# STM32MP21_CA35 register map
File version: 0.4
CPU: CM33 r0p1, little endian, MPU, FPU, vendor SysTick, 8 interrupt priority bits
Registers are 32-bit, read-write, reset 0x0 unless marked. A register's access mark holds for its fields unless they carry their own. Offsets are from the block's base; [hi:lo] are bit positions; {n}, {i} and the like mark numbered series; 'fields as' and 'values as' point back to an identical list.

## RTC — RTC register block
Base 0x46000000
Same registers: RTC_S 0x56000000
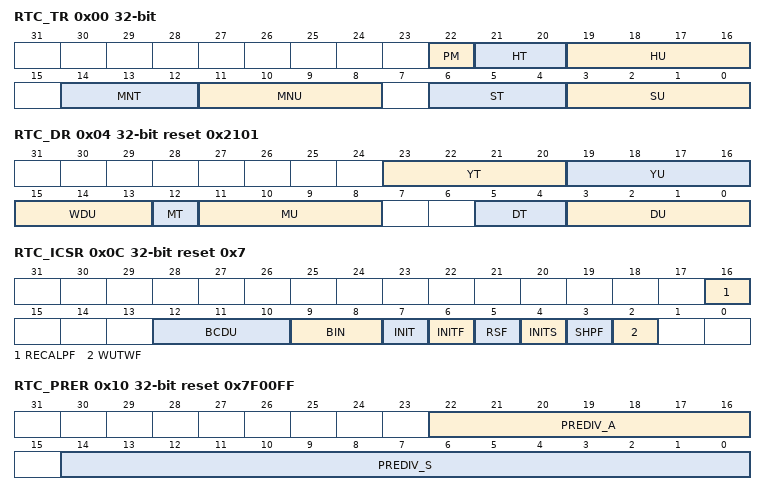
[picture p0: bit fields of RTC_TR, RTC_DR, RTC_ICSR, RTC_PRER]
0x00 RTC_TR — RTC time register
  [22] PM — AM/PM notation
    0=AM or 24-hour format; 1=PM
  [21:20] HT — Hour tens in BCD format
  [19:16] HU — Hour units in BCD format
  [14:12] MNT — Minute tens in BCD format
  [11:8] MNU — Minute units in BCD format
  [6:4] ST — Second tens in BCD format
  [3:0] SU — Second units in BCD format
0x04 RTC_DR reset 0x2101 — RTC date register
  [23:20] YT — Year tens in BCD format
  [19:16] YU — Year units in BCD format
  [15:13] WDU — Week day units
    0=forbidden; 1=Monday; 7=Sunday
  [12] MT — Month tens in BCD format
  [11:8] MU — Month units in BCD format
  [5:4] DT — Date tens in BCD format
  [3:0] DU — Date units in BCD format
0x08 RTC_SSR ro — RTC subsecond register
  [31:0] SS — Synchronous binary counter
0x0C RTC_ICSR reset 0x7 — RTC initialization control and status register
  [16] RECALPF ro — Recalibration pending Flag
  [12:10] BCDU — BCD update (BIN = 10 or 11)
    {v}=1s calendar increment is generated each time SS[{v+7}:0] = 0 (v=0..7)
  [9:8] BIN — Binary mode
    0=Free running BCD calendar mode (Binary mode disabled); 1=Free running Binary mode (BCD mode disabled); 2=Free running BCD calendar and Binary modes; 3=Free running BCD calendar and Binary modes
  [7] INIT — Initialization mode
    0=Free running mode; 1=Initialization mode used to program time and date register (RTC_TR and RTC_DR), and prescaler register (RTC_PRER), plus BIN and BCDU fields
  [6] INITF ro — Initialization flag
    0=Calendar registers update is not allowed; 1=Calendar registers update is allowed
  [5] RSF — Registers synchronization flag
    0=Calendar shadow registers not yet synchronized; 1=Calendar shadow registers synchronized
  [4] INITS ro — Initialization status flag
    0=Calendar has not been initialized; 1=Calendar has been initialized
  [3] SHPF ro — Shift operation pending
    0=No shift operation is pending; 1=A shift operation is pending
  [2] WUTWF ro — Wake-up timer write flag
    0=Wake-up timer configuration update not allowed except in initialization mode; 1=Wake-up timer configuration update allowed
0x10 RTC_PRER reset 0x7F00FF — RTC prescaler register
  [22:16] PREDIV_A — Asynchronous prescaler factor
  [14:0] PREDIV_S — Synchronous prescaler factor
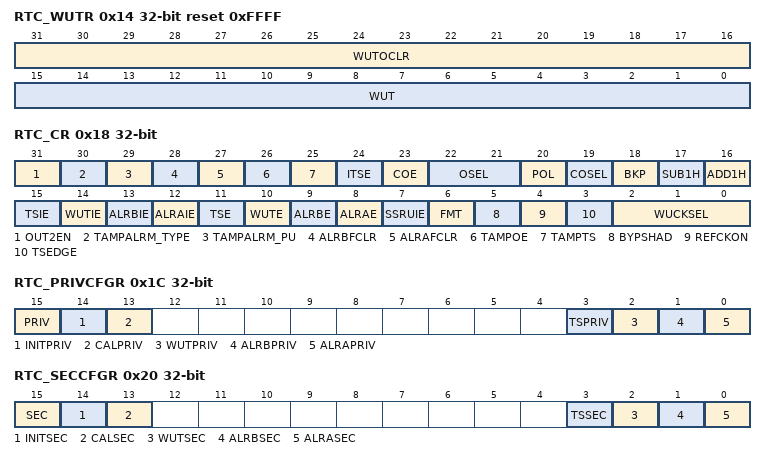
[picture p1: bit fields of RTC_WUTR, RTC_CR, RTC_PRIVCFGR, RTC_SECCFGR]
0x14 RTC_WUTR reset 0xFFFF — RTC wake-up timer register
  [31:16] WUTOCLR — Wake-up auto-reload output clear value
  [15:0] WUT — Wake-up auto-reload value bits
0x18 RTC_CR — RTC control register
  [31] OUT2EN — RTC_OUT2 output enable
  [30] TAMPALRM_TYPE — TAMPALRM output type
    0=TAMPALRM is push-pull output; 1=TAMPALRM is open-drain output
  [29] TAMPALRM_PU — TAMPALRM pull-up enable
    0=No pull-up is applied on TAMPALRM output; 1=A pull-up is applied on TAMPALRM output
  [28] ALRBFCLR — Alarm B flag automatic clear
    0=Alarm B event generates a trigger event and ALRBF must be cleared by software to allow next alarm event; 1=Alarm B event generates a trigger event
  [27] ALRAFCLR — Alarm A flag automatic clear
    0=Alarm A event generates a trigger event and ALRAF must be cleared by software to allow next alarm event; 1=Alarm A event generates a trigger event
  [26] TAMPOE — Tamper detection output enable on TAMPALRM
    0=The tamper flag is not routed on TAMPALRM; 1=The tamper flag is routed on TAMPALRM, combined with the signal provided by OSEL and with the polarity provided by POL
  [25] TAMPTS — Activate timestamp on tamper detection event
    0=Tamper detection event does not cause a RTC timestamp to be saved; 1=Save RTC timestamp on tamper detection event
  [24] ITSE — timestamp on internal event enable
    0=internal event timestamp disabled; 1=internal event timestamp enabled
  [23] COE — Calibration output enable
    0=Calibration output disabled; 1=Calibration output enabled
  [22:21] OSEL — Output selection
    0=Output disabled; 1=Alarm A output enabled; 2=Alarm B output enabled; 3=Wake-up output enabled
  [20] POL — Output polarity
    0=The pin is high when ALRAF/ALRBF/WUTF is asserted (depending on OSEL[1:0]), or when a TAMPxF/ITAMPxF is asserted (if TAMPOE = 1); 1=The pin is low when ALRAF/ALRBF/WUTF is asserted (depending on OSEL[1:0]), or when a TAMPxF/ITAMPxF is asserted (if TAMPOE = 1)
  [19] COSEL — Calibration output selection
    0=Calibration output is 512Hz; 1=Calibration output is 1Hz
  [18] BKP — Backup
  [17] SUB1H wo — Subtract 1 hour (winter time change)
    0=No effect; 1=Subtracts 1 hour to the current time
  [16] ADD1H wo — Add 1 hour (summer time change)
    0=No effect; 1=Adds 1 hour to the current time
  [15] TSIE — Timestamp interrupt enable
    0=Timestamp interrupt disable; 1=Timestamp interrupt enable
  [14] WUTIE — Wake-up timer interrupt enable
    0=Wake-up timer interrupt disabled; 1=Wake-up timer interrupt enabled
  [13] ALRBIE — Alarm B interrupt enable
    0=Alarm B interrupt disable; 1=Alarm B interrupt enable
  [12] ALRAIE — Alarm A interrupt enable
    0=Alarm A interrupt disabled; 1=Alarm A interrupt enabled
  [11] TSE — timestamp enable
    0=timestamp disable; 1=timestamp enable
  [10] WUTE — Wake-up timer enable
    0=Wake-up timer disabled; 1=Wake-up timer enabled
  [9] ALRBE — Alarm B enable
    0=Alarm B disabled; 1=Alarm B enabled
  [8] ALRAE — Alarm A enable
    0=Alarm A disabled; 1=Alarm A enabled
  [7] SSRUIE — SSR underflow interrupt enable
    0=SSR underflow interrupt disabled; 1=SSR underflow interrupt enabled
  [6] FMT — Hour format
    0=24 hour/day format; 1=AM/PM hour format
  [5] BYPSHAD — Bypass the shadow registers
    0=Calendar values (when reading from RTC_SSR, RTC_TR, and RTC_DR) are taken from the shadow registers, which are updated once every two RTCCLK cycles; 1=Calendar values (when reading from RTC_SSR, RTC_TR, and RTC_DR) are taken directly from the calendar counters
  [4] REFCKON — RTC_REFIN reference clock detection enable (50 or 60Hz)
    0=RTC_REFIN detection disabled; 1=RTC_REFIN detection enabled
  [3] TSEDGE — Timestamp event active edge
    0=RTC_TS input rising edge generates a timestamp event; 1=RTC_TS input falling edge generates a timestamp event
  [2:0] WUCKSEL — ck_wut wake-up clock selection
    0=RTC/16 clock is selected; 1=RTC/8 clock is selected; 2=RTC/4 clock is selected; 3=RTC/2 clock is selected
0x1C RTC_PRIVCFGR — RTC privilege mode control register
  [15] PRIV — RTC privilege protection
    0=All RTC registers can be written when the APB access is privileged or non-privileged, except the registers protected by other privilege protection bits; 1=All RTC registers can be written only when the APB access is privileged
  [14] INITPRIV — Initialization privilege protection
    0=RTC Initialization mode, calendar and prescalers registers can be written when the APB access is privileged or non-privileged; 1=RTC Initialization mode, calendar and prescalers registers can be written only when the APB access is privileged
  [13] CALPRIV — Shift register, Delight saving, calibration and reference clock privilege protection
    0=Shift register, Delight saving, calibration and reference clock can be written when the APB access is privileged or non-privileged; 1=Shift register, Delight saving, calibration and reference clock can be written only when the APB access is privileged
  [3] TSPRIV — Timestamp privilege protection
    0=RTC Timestamp configuration and interrupt clear can be written when the APB access is privileged or non-privileged; 1=RTC Timestamp configuration and interrupt clear can be written only when the APB access is privileged
  [2] WUTPRIV — Wake-up timer privilege protection
    0=RTC wake-up timer configuration and interrupt clear can be written when the APB access is privileged or non-privileged; 1=RTC wake-up timer configuration and interrupt clear can be written only when the APB access is privileged
  [1] ALRBPRIV — Alarm B privilege protection
    0=RTC Alarm B configuration and interrupt clear can be written when the APB access is privileged or non-privileged; 1=RTC Alarm B configuration and interrupt clear can be written only when the APB access is privileged
  [0] ALRAPRIV — Alarm A and SSR underflow privilege protection
    0=RTC Alarm A and SSR underflow configuration and interrupt clear can be written when the APB access is privileged or non-privileged; 1=RTC Alarm A and SSR underflow configuration and interrupt clear can be written only when the APB access is privileged
0x20 RTC_SECCFGR — RTC secure configuration register
  [15] SEC — RTC global protection
    0=All RTC registers can be written when the APB access is secure or non-secure, except the registers protected by other secure protection bits; 1=All RTC registers can be written only when the APB access is secure
  [14] INITSEC — Initialization protection
    0=RTC Initialization mode, calendar and prescalers registers can be written when the APB access is secure or nonsecure; 1=RTC Initialization mode, calendar and prescalers registers can be written only when the APB access is secure
  [13] CALSEC — Shift register, daylight saving, calibration and reference clock protection
    0=Shift register, daylight saving, calibration and reference clock can be written when the APB access is secure or nonsecure; 1=Shift register, daylight saving, calibration and reference clock can be written only when the APB access is secure
  [3] TSSEC — Timestamp protection
    0=RTC timestamp configuration and interrupt clear can be written when the APB access is secure or nonsecure; 1=RTC timestamp configuration and interrupt clear can be written only when the APB access is secure
  [2] WUTSEC — Wake-up timer protection
    0=RTC wake-up timer configuration and interrupt clear can be written when the APB access is secure or nonsecure; 1=RTC wake-up timer configuration and interrupt clear can be written only when the APB access is secure
  [1] ALRBSEC — Alarm B protection
    0=RTC alarm B configuration and interrupt clear can be written when the APB access is secure or nonsecure; 1=RTC alarm B configuration and interrupt clear can be written only when the APB access is secure
  [0] ALRASEC — Alarm A and SSR underflow protection
    0=RTC alarm A and SSR underflow configuration and interrupt clear can be written when the APB access is secure or nonsecure; 1=RTC alarm A and SSR underflow configuration and interrupt clear can be written only when the APB access is secure
0x24 RTC_WPR wo — RTC write protection register
  [7:0] KEY — Write protection key
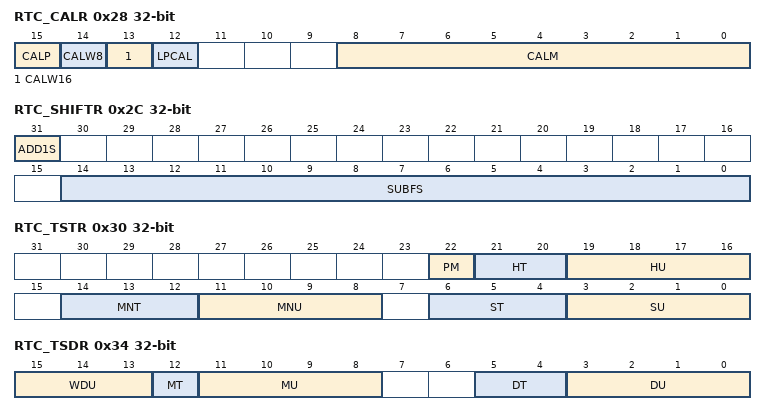
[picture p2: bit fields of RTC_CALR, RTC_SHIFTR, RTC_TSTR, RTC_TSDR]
0x28 RTC_CALR — RTC calibration register
  [15] CALP — Increase frequency of RTC by 488.
    0=No RTCCLK pulses are added; 1=One RTCCLK pulse is effectively inserted every 2less thansup>11less than/sup> pulses (frequency increased by 488
  [14] CALW8 — Use an 8-second calibration cycle period
  [13] CALW16 — Use a 16-second calibration cycle period
  [12] LPCAL — RTC low-power mode
    0=Calibration window is 2less thansup>20less than/sup> RTCCLK, which is a high-consumption mode; 1=Calibration window is 2less thansup>20less than/sup> ck_apre, which is the required configuration for ultra-low consumption mode
  [8:0] CALM — Calibration minus
0x2C RTC_SHIFTR wo — RTC shift control register
  [31] ADD1S — Add one second
    0=No effect; 1=Add one second to the clock/calendar
  [14:0] SUBFS — Subtract a fraction of a second
0x30 RTC_TSTR ro — RTC timestamp time register
  [22] PM — AM/PM notation
    0=AM or 24-hour format; 1=PM
  [21:20] HT — Hour tens in BCD format.
  [19:16] HU — Hour units in BCD format.
  [14:12] MNT — Minute tens in BCD format.
  [11:8] MNU — Minute units in BCD format.
  [6:4] ST — Second tens in BCD format.
  [3:0] SU — Second units in BCD format.
0x34 RTC_TSDR ro — RTC timestamp date register
  [15:13] WDU — Week day units
  [12] MT — Month tens in BCD format
  [11:8] MU — Month units in BCD format
  [5:4] DT — Date tens in BCD format
  [3:0] DU — Date units in BCD format
0x38 RTC_TSSSR ro — RTC timestamp subsecond register
  [31:0] SS — Subsecond value/synchronous binary counter values
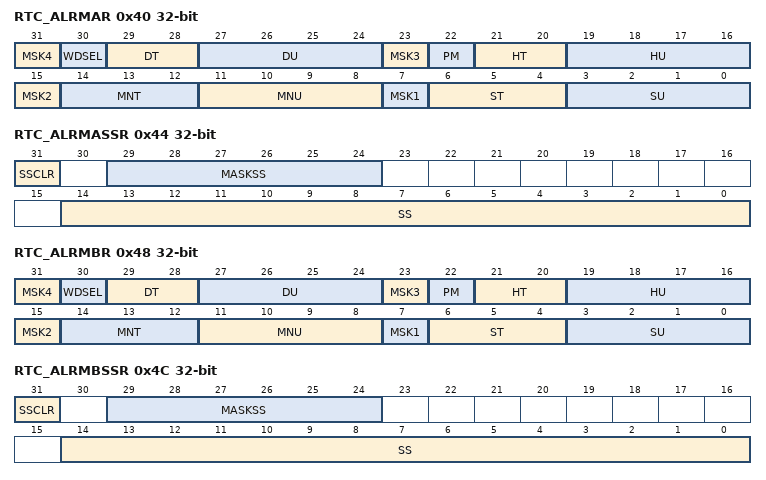
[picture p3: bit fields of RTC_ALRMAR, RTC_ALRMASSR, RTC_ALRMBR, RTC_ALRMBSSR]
0x40 RTC_ALRMAR — RTC alarm A register
  [31] MSK4 — Alarm A date mask
    0=Alarm A set if the date/day match; 1=Date/day don't care in alarm A comparison
  [30] WDSEL — Week day selection
    0=DU[3:0] represents the date units; 1=DU[3:0] represents the week day
  [29:28] DT — Date tens in BCD format
  [27:24] DU — Date units or day in BCD format
  [23] MSK3 — Alarm A hours mask
    0=Alarm A set if the hours match; 1=Hours don't care in alarm A comparison
  [22] PM — AM/PM notation
    0=AM or 24-hour format; 1=PM
  [21:20] HT — Hour tens in BCD format
  [19:16] HU — Hour units in BCD format
  [15] MSK2 — Alarm A minutes mask
    0=Alarm A set if the minutes match; 1=Minutes don't care in alarm A comparison
  [14:12] MNT — Minute tens in BCD format
  [11:8] MNU — Minute units in BCD format
  [7] MSK1 — Alarm A seconds mask
    0=Alarm A set if the seconds match; 1=Seconds don't care in alarm A comparison
  [6:4] ST — Second tens in BCD format.
  [3:0] SU — Second units in BCD format.
0x44 RTC_ALRMASSR — RTC alarm A subsecond register
  [31] SSCLR — Clear synchronous counter on alarm (Binary mode only)
    0=The synchronous binary counter (SS[31:0] in RTC_SSR) is free-running; 1=The synchronous binary counter (SS[31:0] in RTC_SSR) is running from 0xFFFFFFFF to RTC_ALRABINR
  [29:24] MASKSS — Mask the most-significant bits starting at this bit
    0=No comparison on subseconds for Alarm A; 1=SS[31:1] are don't care in Alarm A comparison
  [14:0] SS — Subseconds value
0x48 RTC_ALRMBR — RTC alarm B register
  [31] MSK4 — Alarm B date mask
    0=Alarm B set if the date and day match; 1=Date and day don't care in alarm B comparison
  [30] WDSEL — Week day selection
    values as RTC_ALRMAR.WDSEL
  [29:28] DT — Date tens in BCD format
  [27:24] DU — Date units or day in BCD format
  [23] MSK3 — Alarm B hours mask
    0=Alarm B set if the hours match; 1=Hours don't care in alarm B comparison
  [22] PM — AM/PM notation
    0=AM or 24-hour format; 1=PM
  [21:20] HT — Hour tens in BCD format
  [19:16] HU — Hour units in BCD format
  [15] MSK2 — Alarm B minutes mask
    0=Alarm B set if the minutes match; 1=Minutes don't care in alarm B comparison
  [14:12] MNT — Minute tens in BCD format
  [11:8] MNU — Minute units in BCD format
  [7] MSK1 — Alarm B seconds mask
    0=Alarm B set if the seconds match; 1=Seconds don't care in alarm B comparison
  [6:4] ST — Second tens in BCD format
  [3:0] SU — Second units in BCD format
0x4C RTC_ALRMBSSR — RTC alarm B subsecond register
  [31] SSCLR — Clear synchronous counter on alarm (Binary mode only)
    0=The synchronous binary counter (SS[31:0] in RTC_SSR) is free-running; 1=The synchronous binary counter (SS[31:0] in RTC_SSR) is running from 0xFFFFFFFF to RTC_ALRBBINR
  [29:24] MASKSS — Mask the most-significant bits starting at this bit
    0=No comparison on subseconds for Alarm B; 1=SS[31:1] are don't care in Alarm B comparison
  [14:0] SS — Subseconds value
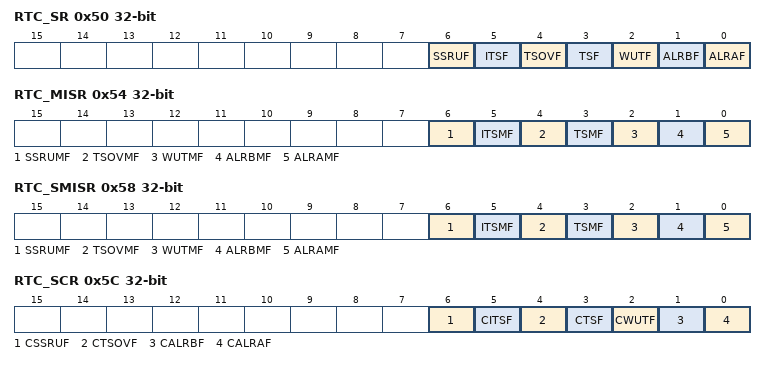
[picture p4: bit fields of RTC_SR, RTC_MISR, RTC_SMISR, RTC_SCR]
0x50 RTC_SR ro — RTC status register
  [6] SSRUF — SSR underflow flag
  [5] ITSF — Internal timestamp flag
  [4] TSOVF — Timestamp overflow flag
  [3] TSF — Timestamp flag
  [2] WUTF — Wake-up timer flag
  [1] ALRBF — Alarm B flag
  [0] ALRAF — Alarm A flag
0x54 RTC_MISR ro — RTC nonsecure masked interrupt status register
  [6] SSRUMF — SSR underflow nonsecure masked flag
  [5] ITSMF — Internal timestamp nonsecure masked flag
  [4] TSOVMF — Timestamp overflow nonsecure masked flag
  [3] TSMF — Timestamp nonsecure masked flag
  [2] WUTMF — Wake-up timer nonsecure masked flag
  [1] ALRBMF — Alarm B nonsecure masked flag
  [0] ALRAMF — Alarm A masked flag
0x58 RTC_SMISR ro — RTC secure masked interrupt status register
  [6] SSRUMF — SSR underflow secure masked flag
  [5] ITSMF — Internal timestamp interrupt secure masked flag
  [4] TSOVMF — Timestamp overflow interrupt secure masked flag
  [3] TSMF — Timestamp interrupt secure masked flag
  [2] WUTMF — Wake-up timer interrupt secure masked flag
  [1] ALRBMF — Alarm B interrupt secure masked flag
  [0] ALRAMF — Alarm A interrupt secure masked flag
0x5C RTC_SCR wo — RTC status clear register
  [6] CSSRUF — Clear SSR underflow flag
  [5] CITSF — Clear internal timestamp flag
  [4] CTSOVF — Clear timestamp overflow flag
  [3] CTSF — Clear timestamp flag
  [2] CWUTF — Clear wake-up timer flag
  [1] CALRBF — Clear alarm B flag
  [0] CALRAF — Clear alarm A flag
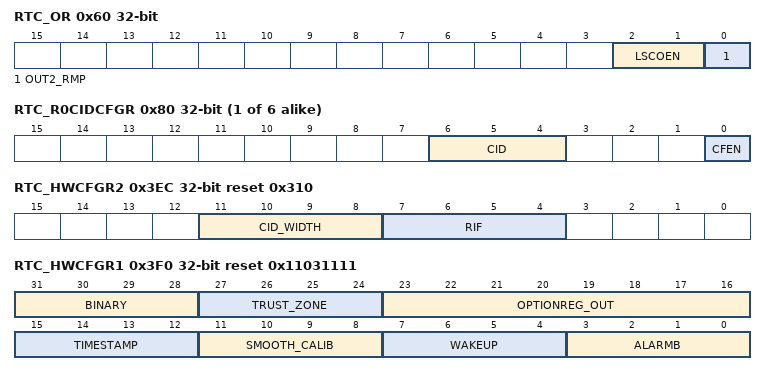
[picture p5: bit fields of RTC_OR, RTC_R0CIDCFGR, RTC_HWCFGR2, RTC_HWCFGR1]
0x60 RTC_OR — RTC option register
  [2:1] LSCOEN — LSCO LSE clock output enable
    0=no effect; 1=LSE is output on PC13; 2=LSE is output on PI8; 3=no effect
  [0] OUT2_RMP — RTC_OUT2 mapping
    0=RTC_OUT2 is mapped on PF6 or PF4 (refer to datasheet); 1=RTC_OUT2 is mapped on PI8
0x70 RTC_ALRABINR — RTC alarm A binary mode register
  [31:0] SS — Synchronous counter alarm value in Binary mode
0x74 RTC_ALRBBINR — RTC alarm B binary mode register
  [31:0] SS — Synchronous counter alarm value in Binary mode
{0x80+4i} RTC_R{i}CIDCFGR (i=0..5)
  [6:4] CID — Compartment identifier
  [0] CFEN — Compartment ID filter enable
    0=Compartment-based filtering is disabled for resource number x; 1=Compartment-based filtering is enabled for resource number x
0x3EC RTC_HWCFGR2 ro reset 0x310 — RTC hardware configuration register 2
  [11:8] CID_WIDTH — CID length
    1=CID length is 1 bit; 2=CID length is 2 bits; 3=CID length is 3 bits; 4=CID length is 4 bits
  [7:4] RIF — CID compartment filtering
    0=CID compartment filtering disable; 1=CID compartment filtering enable
0x3F0 RTC_HWCFGR1 ro reset 0x11031111 — RTC hardware configuration register
  [31:28] BINARY — Binary mode
    0=Binary mode not implemented; 1=Binary mode implemented
  [27:24] TRUST_ZONE
    0=Trust zone not implemented; 1=Trust zone implemented
  [23:16] OPTIONREG_OUT
    0=Configuration register not implemented; 1=Configuration register bit 0 implemented
  [15:12] TIMESTAMP
    0=Timestamp not implemented; 1=Timestamp implemented
  [11:8] SMOOTH_CALIB
    0=Smooth calibration not implemented; 1=Smooth calibration implemented
  [7:4] WAKEUP
    0=Wakeup timer not implemented; 1=Wakeup timer implemented
  [3:0] ALARMB
    0=Alarm B not implemented; 1=Alarm B implemented
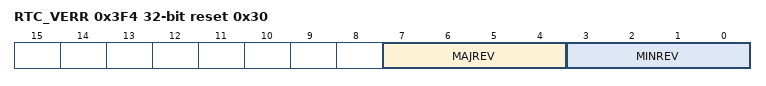
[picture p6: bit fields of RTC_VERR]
0x3F4 RTC_VERR ro reset 0x30 (reset mask 0xFFFFFFF0) — RTC version register
  [7:4] MAJREV — Major revision
  [3:0] MINREV — Minor revision
0x3F8 RTC_IPIDR ro reset 0x120033 — RTC identification register
  [31:0] ID — Identifier
0x3FC RTC_SIDR ro reset 0xA3C5DD01 — RTC size identification register
  [31:0] SID — Size identifier
